# BL808 register map
File version: 0.1
Registers are access not given, no defined reset value unless marked. A register's access mark holds for its fields unless they carry their own. Offsets are from the block's base; [hi:lo] are bit positions; {n}, {i} and the like mark numbered series.

## DBI
Base 0x3001B000
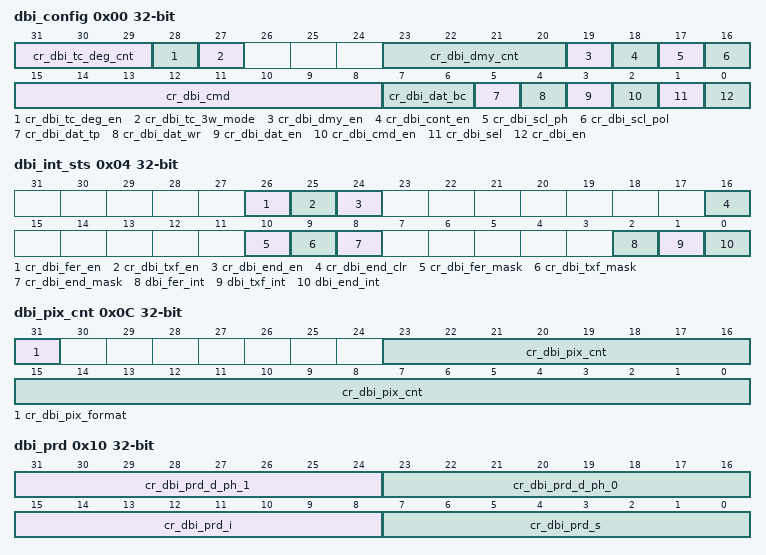
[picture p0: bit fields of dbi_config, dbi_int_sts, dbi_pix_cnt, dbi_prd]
0x00 dbi_config
  [31:29] cr_dbi_tc_deg_cnt rw — De-glitch function cycle count
  [28] cr_dbi_tc_deg_en rw — Enable signal of all input de-glitch function
  [27] cr_dbi_tc_3w_mode rw — DBI Type C 3-wire mode enable 1'b0: 4-wire mode is enabled 1'b1: 3-wire mode is enabled
  [23:20] cr_dbi_dmy_cnt rw — Dummy cycle count, unit: period defined by dbi_prd_d Effective only in Type C (Fixed to 1 dbi_prd_d period in Type B)
  [19] cr_dbi_dmy_en rw — Enable signal of dummy cycle(s) 1'b0: Disabled, no dummy cycle(s) between command phase and data phase 1'b1: Enabled, dummy cycle(s) will be inserted between command phase and data phase
  [18] cr_dbi_cont_en rw — Enable signal of pixel data continuous transfer mode 1'b0: Disabled, CS_n will de-assert between each pixel 1'b1: Enabled, CS_n will stay asserted between each consecutive pixel
  [17] cr_dbi_scl_ph rw — SCL clock phase inverse signal
  [16] cr_dbi_scl_pol rw — SCL clock polarity 0: SCL output LOW at IDLE state 1: SCL output HIGH at IDLE state
  [15:8] cr_dbi_cmd rw — DBI Command
  [7:6] cr_dbi_dat_bc rw — Data byte count of normal data (pixel data count is determined by cr_dbi_pix_cnt)
  [5] cr_dbi_dat_tp rw — Data type select 1'b0: Normal data (parameter) 1'b1: Pixel data Note: Read command supports normal data only
  [4] cr_dbi_dat_wr rw — Data phase Read/Write select 1'b0: Read data 1'b1: Write data
  [3] cr_dbi_dat_en rw — Data enable signal 1'b0: Data phase disabled 1'b1: Data phase enabled
  [2] cr_dbi_cmd_en rw — Command enable signal 1'b0: No command phase 1'b1: Command will be sent
  [1] cr_dbi_sel rw — Select signal of DBI Type B or C 1'b0: DBI Type B 1'b1: DBI Type C
  [0] cr_dbi_en rw — Enable signal of DBI function Asserting this bit will trigger the transaction, and should be de-asserted after finish
0x04 dbi_int_sts
  [26] cr_dbi_fer_en rw — Interrupt enable of dbi_fer_int
  [25] cr_dbi_txf_en rw — Interrupt enable of dbi_txe_int
  [24] cr_dbi_end_en rw — Interrupt enable of dbi_end_int
  [16] cr_dbi_end_clr write-once — Interrupt clear of dbi_end_int
  [10] cr_dbi_fer_mask rw — Interrupt mask of dbi_fer_int
  [9] cr_dbi_txf_mask rw — Interrupt mask of dbi_txe_int
  [8] cr_dbi_end_mask rw — Interrupt mask of dbi_end_int
  [2] dbi_fer_int ro — TX/RX FIFO error interrupt, auto-cleared when FIFO overflow/underflow error flag is cleared
  [1] dbi_txf_int ro — TX FIFO ready (tx_fifo_cnt > tx_fifo_th) interrupt, auto-cleared when data is pushed
  [0] dbi_end_int ro — Transfer end interrupt, shared by both Type B and C mode
0x08 dbi_bus_busy
  [0] sts_dbi_bus_busy ro — Indicator of dbi bus busy
0x0C dbi_pix_cnt
  [31] cr_dbi_pix_format rw — Pixel format 1'b0: RGB565 1'b1: RGB888/RGB666
  [23:0] cr_dbi_pix_cnt rw — Pixel count
0x10 dbi_prd rw
  [31:24] cr_dbi_prd_d_ph_1 — Length of DATA phase 1 (please refer to "Timing" tab)
  [23:16] cr_dbi_prd_d_ph_0 — Length of DATA phase 0 (please refer to "Timing" tab)
  [15:8] cr_dbi_prd_i — Length of INTERVAL between pixel data (please refer to "Timing" tab)
  [7:0] cr_dbi_prd_s — Length of START/STOP condition (please refer to "Timing" tab)
0x18 dbi_wdata rw
  [31:0] cr_dbi_wdata — Data to be written into display IC using write command
0x1C dbi_rdata ro
  [31:0] sts_dbi_rdata — Data read from display IC using read command
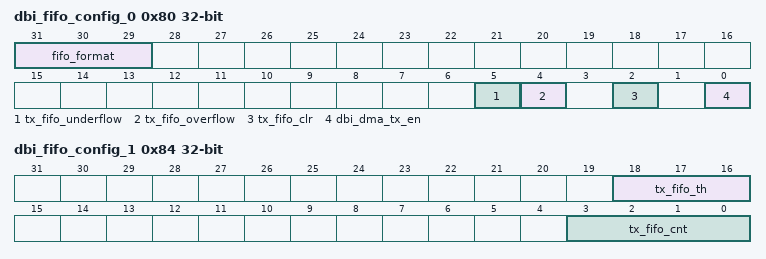
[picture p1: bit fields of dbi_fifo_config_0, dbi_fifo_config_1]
0x80 dbi_fifo_config_0
  [31:29] fifo_format rw — FIFO data format (see Tab 'FIFO Format' for details) 3'd0: {8'h0, B[7:0], G[7:0], R[7:0]} 3'd1: {8'h0, R[7:0], G[7:0], B[7:0]} 3'd2: {B[7:0], G[7:0], R[7:0], 8'h0} 3'd3: {R[7:0], G[7:0], B[7:0], 8'h0} 3'd4: {R[7:0], B[7:0], G[7:0], R[7:0]} 3'd5: {B[7:0], R[7:0], G[7:0], B[7:0]} 3'd6: {2{B[7:3], G[7:2], R[7:3]}} 3'd7: {2{R[7:3], G[7:2], B[7:3]}}
  [5] tx_fifo_underflow ro — Underflow flag of TX FIFO, can be cleared by tx_fifo_clr
  [4] tx_fifo_overflow ro — Overflow flag of TX FIFO, can be cleared by tx_fifo_clr
  [2] tx_fifo_clr write-once — Clear signal of TX FIFO
  [0] dbi_dma_tx_en rw — Enable signal of dma_tx_req/ack interface
0x84 dbi_fifo_config_1
  [18:16] tx_fifo_th rw — TX FIFO threshold, dma_tx_req will not be asserted if tx_fifo_cnt is less than this value
  [3:0] tx_fifo_cnt ro — TX FIFO available count
0x88 dbi_fifo_wdata wo
  [31:0] dbi_fifo_wdata — Pixel data with 8 types of format (determined by fifo_format)
